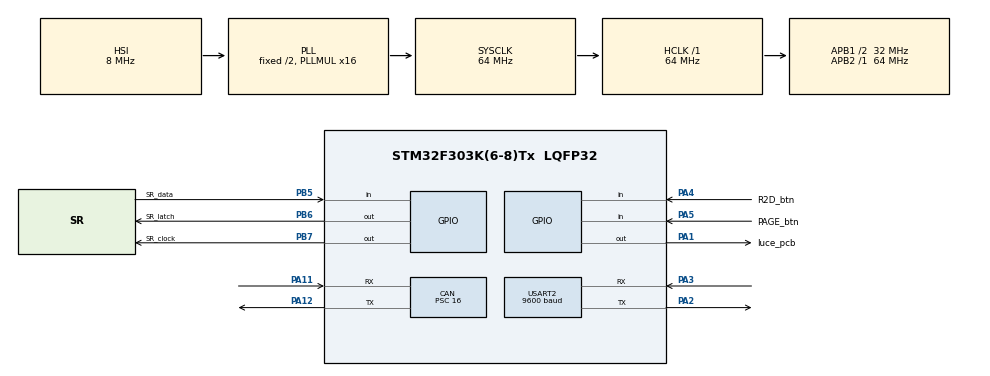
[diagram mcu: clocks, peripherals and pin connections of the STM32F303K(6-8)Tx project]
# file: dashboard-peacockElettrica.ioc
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CAN.ABOM=ENABLE
CAN.BS1=CAN_BS1_2TQ
CAN.BS2=CAN_BS2_1TQ
CAN.CalculateBaudRate=500000
CAN.CalculateTimeBit=2000
CAN.CalculateTimeQuantum=500.0
CAN.Prescaler=16
CAN.SJW=CAN_SJW_2TQ
Dma.Request0=USART2_TX
Dma.USART2_TX.0.Direction=DMA_MEMORY_TO_PERIPH
Dma.USART2_TX.0.Instance=DMA1_Channel7
Dma.USART2_TX.0.MemDataAlignment=DMA_MDATAALIGN_BYTE
Dma.USART2_TX.0.MemInc=DMA_MINC_ENABLE
Dma.USART2_TX.0.Mode=DMA_NORMAL
Dma.USART2_TX.0.PeriphDataAlignment=DMA_PDATAALIGN_BYTE
Dma.USART2_TX.0.PeriphInc=DMA_PINC_DISABLE
Dma.USART2_TX.0.Priority=DMA_PRIORITY_MEDIUM
Mcu.Family=STM32F3
Mcu.Name=STM32F303K(6-8)Tx
Mcu.Package=LQFP32
NVIC.CAN_RX0_IRQn=true\:0\:0\:false\:false\:true\:true\:true\:true
NVIC.DMA1_Channel7_IRQn=true\:0\:0\:false\:false\:true\:false\:true\:true
NVIC.PriorityGroup=NVIC_PRIORITYGROUP_4
NVIC.USART2_IRQn=true\:0\:0\:false\:false\:true\:false\:true\:true
PA1.GPIO_Label=luce_pcb
PA1.Signal=GPIO_Output
PA11.Mode=CAN_Activate
PA11.Signal=CAN_RX
PA12.Mode=CAN_Activate
PA12.Signal=CAN_TX
PA13.Mode=Serial_Wire
PA13.Signal=SYS_JTMS-SWDIO
PA14.Mode=Serial_Wire
PA14.Signal=SYS_JTCK-SWCLK
PA2.GPIO_Speed=GPIO_SPEED_FREQ_HIGH
PA2.Mode=Asynchronous
PA2.Signal=USART2_TX
PA3.Mode=Asynchronous
PA3.Signal=USART2_RX
PA4.GPIO_Label=R2D_btn
PA4.Signal=GPIO_Input
PA5.GPIO_Label=PAGE_btn
PA5.Signal=GPIO_Input
PB5.GPIO_Label=SR_data
PB5.Signal=GPIO_Input
PB6.GPIO_Label=SR_latch
PB6.GPIO_Speed=GPIO_SPEED_FREQ_HIGH
PB6.Signal=GPIO_Output
PB7.GPIO_Label=SR_clock
PB7.GPIO_Speed=GPIO_SPEED_FREQ_HIGH
PB7.Signal=GPIO_Output
PF0\ /\ OSC_IN.Mode=HSE-External-Oscillator
PF0\ /\ OSC_IN.Signal=RCC_OSC_IN
PF1\ /\ OSC_OUT.Mode=HSE-External-Oscillator
PF1\ /\ OSC_OUT.Signal=RCC_OSC_OUT
ProjectManager.HeapSize=0x200
ProjectManager.StackSize=0x400
ProjectManager.TargetToolchain=STM32CubeIDE
RCC.AHBFreq_Value=64000000
RCC.APB1CLKDivider=RCC_HCLK_DIV2
RCC.APB1Freq_Value=32000000
RCC.APB1TimFreq_Value=64000000
RCC.APB2Freq_Value=64000000
RCC.APB2TimFreq_Value=64000000
RCC.CortexFreq_Value=64000000
RCC.HCLKFreq_Value=64000000
RCC.HSE_VALUE=12000000
RCC.HSI_VALUE=8000000
RCC.PLLMUL=RCC_PLL_MUL16
RCC.RCC_PLLsource_Clock_Source_FROM_HSE=RCC_HSE_PREDIV_DIV3
RCC.SYSCLKFreq_VALUE=64000000
RCC.SYSCLKSourceVirtual=RCC_SYSCLKSOURCE_PLLCLK
USART2.BaudRate=9600
USART2.VirtualMode-Asynchronous=VM_ASYNC
board=custom

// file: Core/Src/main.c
/* USER CODE BEGIN Header */
/**
  ******************************************************************************
  * @file           : main.c
  * @brief          : Main program body
  ******************************************************************************
  * @attention
  *
  * Copyright (c) 2026 STMicroelectronics.
  * All rights reserved.
  *
  * This software is licensed under terms that can be found in the LICENSE file
  * in the root directory of this software component.
  * If no LICENSE file comes with this software, it is provided AS-IS.
  *
  ******************************************************************************
  */
/* USER CODE END Header */
#include "main.h"

/* USER CODE BEGIN Includes */
#include "Scheduler.h"
#include "Tasks.h"
#include "serial.h"
#include "can.h"
/* USER CODE END Includes */

CAN_HandleTypeDef hcan;

UART_HandleTypeDef huart2;
DMA_HandleTypeDef hdma_usart2_tx;

void SystemClock_Config(void);
static void MX_GPIO_Init(void);
static void MX_DMA_Init(void);
static void MX_CAN_Init(void);
static void MX_USART2_UART_Init(void);

int main(void)
{

  /* MCU Configuration--------------------------------------------------------*/

  /* Reset of all peripherals, Initializes the Flash interface and the Systick. */
  HAL_Init();

  /* Configure the system clock */
  SystemClock_Config();

  /* Initialize all configured peripherals */
  MX_GPIO_Init();
  MX_DMA_Init();
  MX_CAN_Init();
  MX_USART2_UART_Init();
  /* USER CODE BEGIN 2 */
  SchedulerInit();

  char test_msg[] = "CIAO! La Seriale Funziona!\r\n";
  HAL_UART_Transmit(&huart2, (uint8_t*)test_msg, strlen(test_msg), 1000);
  /* USER CODE END 2 */

  /* Infinite loop */
  /* USER CODE BEGIN WHILE */
  while (1)
  {
	  SchedulerManagementFunction();

	  /*
	  char test_msg[] = "Ciao dal volante!\r\n";
	  HAL_UART_Transmit(&huart2, (uint8_t*)test_msg, strlen(test_msg), 1000);
	  HAL_Delay(1000);
	  */

	  if(HAL_GetTick() % 1000 == 0){
		 // HAL_GPIO_TogglePin(luce_pcb_GPIO_Port,luce_pcb_Pin);
	  }
    /* USER CODE END WHILE */

  }
}

void SystemClock_Config(void)
{
  RCC_OscInitTypeDef RCC_OscInitStruct = {0};
  RCC_ClkInitTypeDef RCC_ClkInitStruct = {0};

  /** Initializes the RCC Oscillators according to the specified parameters
  * in the RCC_OscInitTypeDef structure.
  */
  RCC_OscInitStruct.OscillatorType = RCC_OSCILLATORTYPE_HSI;
  RCC_OscInitStruct.HSIState = RCC_HSI_ON;
  RCC_OscInitStruct.HSICalibrationValue = RCC_HSICALIBRATION_DEFAULT;
  RCC_OscInitStruct.PLL.PLLState = RCC_PLL_ON;
  RCC_OscInitStruct.PLL.PLLSource = RCC_PLLSOURCE_HSI;
  RCC_OscInitStruct.PLL.PLLMUL = RCC_PLL_MUL16;
  if (HAL_RCC_OscConfig(&RCC_OscInitStruct) != HAL_OK)
  {
    Error_Handler();
  }

  /** Initializes the CPU, AHB and APB buses clocks
  */
  RCC_ClkInitStruct.ClockType = RCC_CLOCKTYPE_HCLK|RCC_CLOCKTYPE_SYSCLK
                              |RCC_CLOCKTYPE_PCLK1|RCC_CLOCKTYPE_PCLK2;
  RCC_ClkInitStruct.SYSCLKSource = RCC_SYSCLKSOURCE_PLLCLK;
  RCC_ClkInitStruct.AHBCLKDivider = RCC_SYSCLK_DIV1;
  RCC_ClkInitStruct.APB1CLKDivider = RCC_HCLK_DIV2;
  RCC_ClkInitStruct.APB2CLKDivider = RCC_HCLK_DIV1;

  if (HAL_RCC_ClockConfig(&RCC_ClkInitStruct, FLASH_LATENCY_2) != HAL_OK)
  {
    Error_Handler();
  }
}

static void MX_CAN_Init(void)
{

  hcan.Instance = CAN;
  hcan.Init.Prescaler = 16;
  hcan.Init.Mode = CAN_MODE_NORMAL;
  hcan.Init.SyncJumpWidth = CAN_SJW_2TQ;
  hcan.Init.TimeSeg1 = CAN_BS1_2TQ;
  hcan.Init.TimeSeg2 = CAN_BS2_1TQ;
  hcan.Init.TimeTriggeredMode = DISABLE;
  hcan.Init.AutoBusOff = ENABLE;
  hcan.Init.AutoWakeUp = DISABLE;
  hcan.Init.AutoRetransmission = DISABLE;
  hcan.Init.ReceiveFifoLocked = DISABLE;
  hcan.Init.TransmitFifoPriority = DISABLE;
  if (HAL_CAN_Init(&hcan) != HAL_OK)
  {
    Error_Handler();
  }

}

static void MX_USART2_UART_Init(void)
{

  huart2.Instance = USART2;
  huart2.Init.BaudRate = 9600;
  huart2.Init.WordLength = UART_WORDLENGTH_8B;
  huart2.Init.StopBits = UART_STOPBITS_1;
  huart2.Init.Parity = UART_PARITY_NONE;
  huart2.Init.Mode = UART_MODE_TX_RX;
  huart2.Init.HwFlowCtl = UART_HWCONTROL_NONE;
  huart2.Init.OverSampling = UART_OVERSAMPLING_16;
  huart2.Init.OneBitSampling = UART_ONE_BIT_SAMPLE_DISABLE;
  huart2.AdvancedInit.AdvFeatureInit = UART_ADVFEATURE_NO_INIT;
  if (HAL_UART_Init(&huart2) != HAL_OK)
  {
    Error_Handler();
  }

}

static void MX_DMA_Init(void)
{

  /* DMA controller clock enable */
  __HAL_RCC_DMA1_CLK_ENABLE();

  /* DMA interrupt init */
  /* DMA1_Channel7_IRQn interrupt configuration */
  HAL_NVIC_SetPriority(DMA1_Channel7_IRQn, 0, 0);
  HAL_NVIC_EnableIRQ(DMA1_Channel7_IRQn);

}

static void MX_GPIO_Init(void)
{
  GPIO_InitTypeDef GPIO_InitStruct = {0};

  /* GPIO Ports Clock Enable */
  __HAL_RCC_GPIOF_CLK_ENABLE();
  __HAL_RCC_GPIOA_CLK_ENABLE();
  __HAL_RCC_GPIOB_CLK_ENABLE();

  /*Configure GPIO pin Output Level */
  HAL_GPIO_WritePin(luce_pcb_GPIO_Port, luce_pcb_Pin, GPIO_PIN_RESET);

  /*Configure GPIO pin Output Level */
  HAL_GPIO_WritePin(GPIOB, SR_latch_Pin|SR_clock_Pin, GPIO_PIN_RESET);

  /*Configure GPIO pin : luce_pcb_Pin */
  GPIO_InitStruct.Pin = luce_pcb_Pin;
  GPIO_InitStruct.Mode = GPIO_MODE_OUTPUT_PP;
  GPIO_InitStruct.Pull = GPIO_NOPULL;
  GPIO_InitStruct.Speed = GPIO_SPEED_FREQ_LOW;
  HAL_GPIO_Init(luce_pcb_GPIO_Port, &GPIO_InitStruct);

  /*Configure GPIO pins : R2D_btn_Pin PAGE_btn_Pin */
  GPIO_InitStruct.Pin = R2D_btn_Pin|PAGE_btn_Pin;
  GPIO_InitStruct.Mode = GPIO_MODE_INPUT;
  GPIO_InitStruct.Pull = GPIO_NOPULL;
  HAL_GPIO_Init(GPIOA, &GPIO_InitStruct);

  /*Configure GPIO pin : SR_data_Pin */
  GPIO_InitStruct.Pin = SR_data_Pin;
  GPIO_InitStruct.Mode = GPIO_MODE_INPUT;
  GPIO_InitStruct.Pull = GPIO_NOPULL;
  HAL_GPIO_Init(SR_data_GPIO_Port, &GPIO_InitStruct);

  /*Configure GPIO pins : SR_latch_Pin SR_clock_Pin */
  GPIO_InitStruct.Pin = SR_latch_Pin|SR_clock_Pin;
  GPIO_InitStruct.Mode = GPIO_MODE_OUTPUT_PP;
  GPIO_InitStruct.Pull = GPIO_NOPULL;
  GPIO_InitStruct.Speed = GPIO_SPEED_FREQ_HIGH;
  HAL_GPIO_Init(GPIOB, &GPIO_InitStruct);

}

/* USER CODE BEGIN 4 */
void HAL_CAN_RxFifo0MsgPendingCallback(CAN_HandleTypeDef* hcan){
  Receive_CAN_Message(hcan);
}

void HAL_UART_TxCpltCallback(UART_HandleTypeDef *huart)
{
    // Quando il DMA finisce di inviare i dati, libera il flag!
    if (huart->Instance == USART2)
    {
        uart2_tx_busy = 0;
    }
}

/* USER CODE END 4 */

void Error_Handler(void)
{
  __disable_irq();
  while (1)
  {
  }
}
